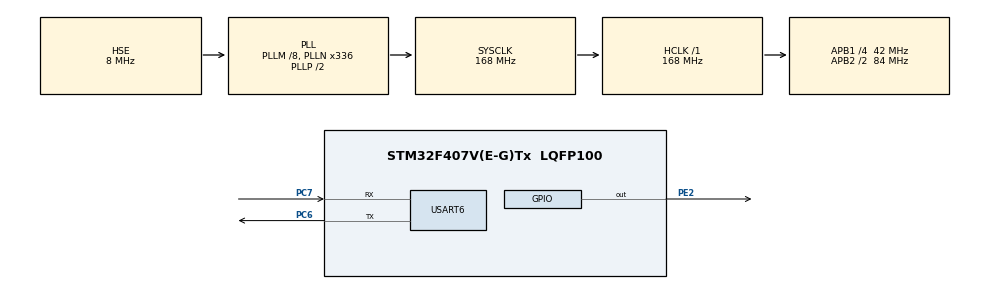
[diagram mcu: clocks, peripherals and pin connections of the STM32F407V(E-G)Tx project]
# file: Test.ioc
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Mcu.Family=STM32F4
Mcu.Name=STM32F407V(E-G)Tx
Mcu.Package=LQFP100
NVIC.PriorityGroup=NVIC_PRIORITYGROUP_4
NVIC.USART6_IRQn=true\:0\:0\:false\:true\:true\:1\:true\:true\:true
PC6.Mode=Asynchronous
PC6.Signal=USART6_TX
PC7.Mode=Asynchronous
PC7.Signal=USART6_RX
PE2.Signal=GPIO_Output
PH0-OSC_IN.Mode=HSE-External-Oscillator
PH0-OSC_IN.Signal=RCC_OSC_IN
PH1-OSC_OUT.Mode=HSE-External-Oscillator
PH1-OSC_OUT.Signal=RCC_OSC_OUT
ProjectManager.HeapSize=0x200
ProjectManager.StackSize=0x400
ProjectManager.TargetToolchain=MDK-ARM V5.32
RCC.48MHZClocksFreq_Value=84000000
RCC.AHBFreq_Value=168000000
RCC.APB1CLKDivider=RCC_HCLK_DIV4
RCC.APB1Freq_Value=42000000
RCC.APB1TimFreq_Value=84000000
RCC.APB2CLKDivider=RCC_HCLK_DIV2
RCC.APB2Freq_Value=84000000
RCC.APB2TimFreq_Value=168000000
RCC.CortexFreq_Value=168000000
RCC.HCLKFreq_Value=168000000
RCC.HSE_VALUE=8000000
RCC.HSI_VALUE=16000000
RCC.LSE_VALUE=32768
RCC.PLLM=8
RCC.PLLN=336
RCC.PLLSourceVirtual=RCC_PLLSOURCE_HSE
RCC.SYSCLKFreq_VALUE=168000000
RCC.SYSCLKSource=RCC_SYSCLKSOURCE_PLLCLK
RCC.VCOOutputFreq_Value=336000000
USART6.VirtualMode=VM_ASYNC
board=custom

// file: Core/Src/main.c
/* USER CODE BEGIN Header */
/**
  ******************************************************************************
  * @file           : main.c
  * @brief          : Main program body
  ******************************************************************************
  * @attention
  *
  * Copyright (c) 2025 STMicroelectronics.
  * All rights reserved.
  *
  * This software is licensed under terms that can be found in the LICENSE file
  * in the root directory of this software component.
  * If no LICENSE file comes with this software, it is provided AS-IS.
  *
  ******************************************************************************
  */
/* USER CODE END Header */
#include "main.h"

/* USER CODE BEGIN Includes */
#include "wexcube.h"
#include <stdlib.h>
#include <string.h>
#include <stdio.h>
/* USER CODE END Includes */

/* USER CODE BEGIN PD */
#define FIRMWARE_VERSION				0x14				// 固件版本号
#define TEXT_VERSION_ID					1						// WeXCube 小程序显示程序版本的文本控件
/* USER CODE END PD */

UART_HandleTypeDef huart6;

void SystemClock_Config(void);
static void MX_GPIO_Init(void);
static void MX_USART6_UART_Init(void);
static void MX_NVIC_Init(void);

int main(void)
{

  /* MCU Configuration--------------------------------------------------------*/

  /* Reset of all peripherals, Initializes the Flash interface and the Systick. */
  HAL_Init();

  /* Configure the system clock */
  SystemClock_Config();

  /* Initialize all configured peripherals */
  MX_GPIO_Init();
  MX_USART6_UART_Init();

  /* Initialize interrupts */
  MX_NVIC_Init();
  /* USER CODE BEGIN 2 */
	wex_init();
	wex_start();

	// 开启接收中断
	__HAL_UART_ENABLE_IT(&huart6, UART_IT_RXNE);

	// 恢复中断
	__enable_irq();
  /* USER CODE END 2 */

  /* Infinite loop */
  /* USER CODE BEGIN WHILE */
  while (1)
  {
		const t_sWexCmd *psWexCmd = wex_process();
    switch (psWexCmd->eCmdType)
    {
			case eWexCmd_Connect:	// 连接指令
			{
				// 通过版本号可知升级是否成功
				wex_setText(TEXT_VERSION_ID, wex_uintToStr(FIRMWARE_VERSION));
			}
			break;

			case eWexCmd_Upgrade:	// 升级数据
			{
				// 升级数据包编号错误，请求重新传输
				if (psWexCmd->sUpgrade.usPackNo == 0)
				{
					// 升级开始，软件复位进入 Bootloader
					NVIC_SystemReset();
					while (1);
				}
			}
			break;

			default:
      break;
    }
    /* USER CODE END WHILE */

  }
}

void SystemClock_Config(void)
{
  RCC_OscInitTypeDef RCC_OscInitStruct = {0};
  RCC_ClkInitTypeDef RCC_ClkInitStruct = {0};

  /** Configure the main internal regulator output voltage
  */
  __HAL_RCC_PWR_CLK_ENABLE();
  __HAL_PWR_VOLTAGESCALING_CONFIG(PWR_REGULATOR_VOLTAGE_SCALE1);

  /** Initializes the RCC Oscillators according to the specified parameters
  * in the RCC_OscInitTypeDef structure.
  */
  RCC_OscInitStruct.OscillatorType = RCC_OSCILLATORTYPE_HSE;
  RCC_OscInitStruct.HSEState = RCC_HSE_ON;
  RCC_OscInitStruct.PLL.PLLState = RCC_PLL_ON;
  RCC_OscInitStruct.PLL.PLLSource = RCC_PLLSOURCE_HSE;
  RCC_OscInitStruct.PLL.PLLM = 8;
  RCC_OscInitStruct.PLL.PLLN = 336;
  RCC_OscInitStruct.PLL.PLLP = RCC_PLLP_DIV2;
  RCC_OscInitStruct.PLL.PLLQ = 4;
  if (HAL_RCC_OscConfig(&RCC_OscInitStruct) != HAL_OK)
  {
    Error_Handler();
  }

  /** Initializes the CPU, AHB and APB buses clocks
  */
  RCC_ClkInitStruct.ClockType = RCC_CLOCKTYPE_HCLK|RCC_CLOCKTYPE_SYSCLK
                              |RCC_CLOCKTYPE_PCLK1|RCC_CLOCKTYPE_PCLK2;
  RCC_ClkInitStruct.SYSCLKSource = RCC_SYSCLKSOURCE_PLLCLK;
  RCC_ClkInitStruct.AHBCLKDivider = RCC_SYSCLK_DIV1;
  RCC_ClkInitStruct.APB1CLKDivider = RCC_HCLK_DIV4;
  RCC_ClkInitStruct.APB2CLKDivider = RCC_HCLK_DIV2;

  if (HAL_RCC_ClockConfig(&RCC_ClkInitStruct, FLASH_LATENCY_5) != HAL_OK)
  {
    Error_Handler();
  }
}

/**
  * @brief NVIC Configuration.
  * @retval None
  */
static void MX_NVIC_Init(void)
{
  /* USART6_IRQn interrupt configuration */
  HAL_NVIC_SetPriority(USART6_IRQn, 0, 0);
  HAL_NVIC_EnableIRQ(USART6_IRQn);
}

static void MX_USART6_UART_Init(void)
{

  huart6.Instance = USART6;
  huart6.Init.BaudRate = 115200;
  huart6.Init.WordLength = UART_WORDLENGTH_8B;
  huart6.Init.StopBits = UART_STOPBITS_1;
  huart6.Init.Parity = UART_PARITY_NONE;
  huart6.Init.Mode = UART_MODE_TX_RX;
  huart6.Init.HwFlowCtl = UART_HWCONTROL_NONE;
  huart6.Init.OverSampling = UART_OVERSAMPLING_16;
  if (HAL_UART_Init(&huart6) != HAL_OK)
  {
    Error_Handler();
  }

}

static void MX_GPIO_Init(void)
{
  GPIO_InitTypeDef GPIO_InitStruct = {0};

  /* GPIO Ports Clock Enable */
  __HAL_RCC_GPIOE_CLK_ENABLE();
  __HAL_RCC_GPIOH_CLK_ENABLE();
  __HAL_RCC_GPIOC_CLK_ENABLE();

  /*Configure GPIO pin Output Level */
  HAL_GPIO_WritePin(GPIOE, GPIO_PIN_2, GPIO_PIN_RESET);

  /*Configure GPIO pin : PE2 */
  GPIO_InitStruct.Pin = GPIO_PIN_2;
  GPIO_InitStruct.Mode = GPIO_MODE_OUTPUT_PP;
  GPIO_InitStruct.Pull = GPIO_NOPULL;
  GPIO_InitStruct.Speed = GPIO_SPEED_FREQ_LOW;
  HAL_GPIO_Init(GPIOE, &GPIO_InitStruct);

}

void Error_Handler(void)
{
  __disable_irq();
  while (1)
  {
  }
}
